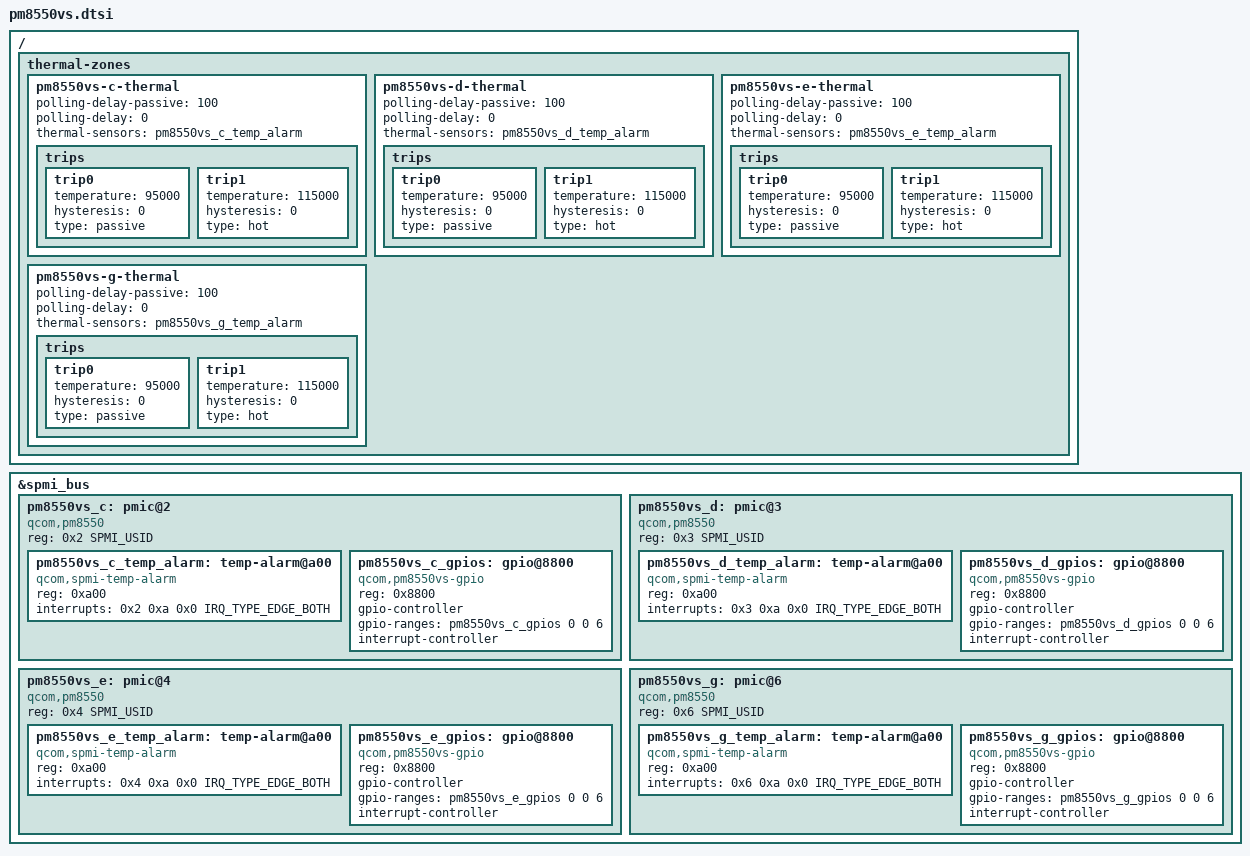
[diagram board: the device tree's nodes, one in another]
// SPDX-License-Identifier: BSD-3-Clause
/*
 * Copyright (c) 2022, Linaro Limited
 */

#include <dt-bindings/interrupt-controller/irq.h>
#include <dt-bindings/spmi/spmi.h>

/ {
	thermal-zones {
		pm8550vs-c-thermal {
			polling-delay-passive = <100>;
			polling-delay = <0>;

			thermal-sensors = <&pm8550vs_c_temp_alarm>;

			trips {
				trip0 {
					temperature = <95000>;
					hysteresis = <0>;
					type = "passive";
				};

				trip1 {
					temperature = <115000>;
					hysteresis = <0>;
					type = "hot";
				};
			};
		};

		pm8550vs-d-thermal {
			polling-delay-passive = <100>;
			polling-delay = <0>;

			thermal-sensors = <&pm8550vs_d_temp_alarm>;

			trips {
				trip0 {
					temperature = <95000>;
					hysteresis = <0>;
					type = "passive";
				};

				trip1 {
					temperature = <115000>;
					hysteresis = <0>;
					type = "hot";
				};
			};
		};

		pm8550vs-e-thermal {
			polling-delay-passive = <100>;
			polling-delay = <0>;

			thermal-sensors = <&pm8550vs_e_temp_alarm>;

			trips {
				trip0 {
					temperature = <95000>;
					hysteresis = <0>;
					type = "passive";
				};

				trip1 {
					temperature = <115000>;
					hysteresis = <0>;
					type = "hot";
				};
			};
		};

		pm8550vs-g-thermal {
			polling-delay-passive = <100>;
			polling-delay = <0>;

			thermal-sensors = <&pm8550vs_g_temp_alarm>;

			trips {
				trip0 {
					temperature = <95000>;
					hysteresis = <0>;
					type = "passive";
				};

				trip1 {
					temperature = <115000>;
					hysteresis = <0>;
					type = "hot";
				};
			};
		};
	};
};


&spmi_bus {
	pm8550vs_c: pmic@2 {
		compatible = "qcom,pm8550", "qcom,spmi-pmic";
		reg = <0x2 SPMI_USID>;
		#address-cells = <1>;
		#size-cells = <0>;

		pm8550vs_c_temp_alarm: temp-alarm@a00 {
			compatible = "qcom,spmi-temp-alarm";
			reg = <0xa00>;
			interrupts = <0x2 0xa 0x0 IRQ_TYPE_EDGE_BOTH>;
			#thermal-sensor-cells = <0>;
		};

		pm8550vs_c_gpios: gpio@8800 {
			compatible = "qcom,pm8550vs-gpio", "qcom,spmi-gpio";
			reg = <0x8800>;
			gpio-controller;
			gpio-ranges = <&pm8550vs_c_gpios 0 0 6>;
			#gpio-cells = <2>;
			interrupt-controller;
			#interrupt-cells = <2>;
		};
	};

	pm8550vs_d: pmic@3 {
		compatible = "qcom,pm8550", "qcom,spmi-pmic";
		reg = <0x3 SPMI_USID>;
		#address-cells = <1>;
		#size-cells = <0>;

		pm8550vs_d_temp_alarm: temp-alarm@a00 {
			compatible = "qcom,spmi-temp-alarm";
			reg = <0xa00>;
			interrupts = <0x3 0xa 0x0 IRQ_TYPE_EDGE_BOTH>;
			#thermal-sensor-cells = <0>;
		};

		pm8550vs_d_gpios: gpio@8800 {
			compatible = "qcom,pm8550vs-gpio", "qcom,spmi-gpio";
			reg = <0x8800>;
			gpio-controller;
			gpio-ranges = <&pm8550vs_d_gpios 0 0 6>;
			#gpio-cells = <2>;
			interrupt-controller;
			#interrupt-cells = <2>;
		};
	};

	pm8550vs_e: pmic@4 {
		compatible = "qcom,pm8550", "qcom,spmi-pmic";
		reg = <0x4 SPMI_USID>;
		#address-cells = <1>;
		#size-cells = <0>;

		pm8550vs_e_temp_alarm: temp-alarm@a00 {
			compatible = "qcom,spmi-temp-alarm";
			reg = <0xa00>;
			interrupts = <0x4 0xa 0x0 IRQ_TYPE_EDGE_BOTH>;
			#thermal-sensor-cells = <0>;
		};

		pm8550vs_e_gpios: gpio@8800 {
			compatible = "qcom,pm8550vs-gpio", "qcom,spmi-gpio";
			reg = <0x8800>;
			gpio-controller;
			gpio-ranges = <&pm8550vs_e_gpios 0 0 6>;
			#gpio-cells = <2>;
			interrupt-controller;
			#interrupt-cells = <2>;
		};
	};

	pm8550vs_g: pmic@6 {
		compatible = "qcom,pm8550", "qcom,spmi-pmic";
		reg = <0x6 SPMI_USID>;
		#address-cells = <1>;
		#size-cells = <0>;

		pm8550vs_g_temp_alarm: temp-alarm@a00 {
			compatible = "qcom,spmi-temp-alarm";
			reg = <0xa00>;
			interrupts = <0x6 0xa 0x0 IRQ_TYPE_EDGE_BOTH>;
			#thermal-sensor-cells = <0>;
		};

		pm8550vs_g_gpios: gpio@8800 {
			compatible = "qcom,pm8550vs-gpio", "qcom,spmi-gpio";
			reg = <0x8800>;
			gpio-controller;
			gpio-ranges = <&pm8550vs_g_gpios 0 0 6>;
			#gpio-cells = <2>;
			interrupt-controller;
			#interrupt-cells = <2>;
		};
	};
};
